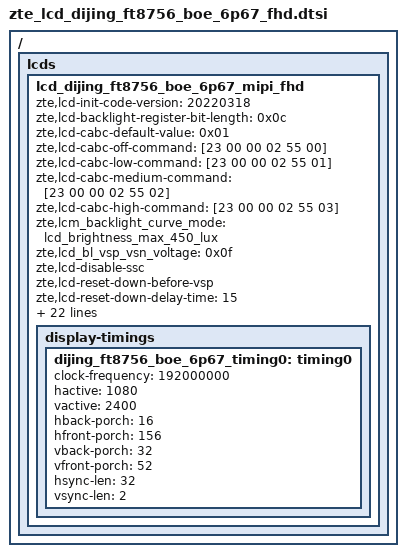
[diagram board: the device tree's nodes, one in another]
/ { lcds {
	lcd_dijing_ft8756_boe_6p67_mipi_fhd: lcd_dijing_ft8756_boe_6p67_mipi_fhd {
		zte,lcd-init-code-version = "20220318";
		zte,lcd-backlight-register-bit-length = <0x0c>;
		zte,lcd-cabc-default-value = <0x01>;
		zte,lcd-cabc-off-command = [23 00 00 02 55 00];
		zte,lcd-cabc-low-command = [23 00 00 02 55 01];
		zte,lcd-cabc-medium-command = [23 00 00 02 55 02];
		zte,lcd-cabc-high-command = [23 00 00 02 55 03];
		zte,lcm_backlight_curve_mode = "lcd_brightness_max_450_lux";
		zte,lcd_bl_vsp_vsn_voltage = <0x0f>;
		zte,lcd-disable-ssc;
		zte,lcd-reset-down-before-vsp;
		zte,lcd-reset-down-delay-time = <15>;
		zte,panel-name = "lcd_dijing_focal_ft8756_boe_6p67_mipi_fhd";

		sprd,dsi-work-mode = <1>; /* video burst mode*/
		sprd,dsi-lane-number = <4>;
		sprd,dsi-color-format = "rgb888";

		sprd,phy-bit-clock = <1296000>;  /* kbps */
		sprd,phy-escape-clock = <20000>;/* kHz */

		sprd,width-mm = <69498>;
		sprd,height-mm = <154440>;

		sprd,esd-check-enable = <0>;/* 0:close , 1:open */
		sprd,esd-check-mode = <0>;/* 0:REG ,1:TE  */
		sprd,esd-check-period = <3000>;
		sprd,esd-check-register = <0x0A>;
		sprd,esd-check-value = <0x9c>;

		sprd,reset-on-sequence = <1 10>, <0 10>, <1 50>;
		sprd,reset-off-sequence = <1 5>;

		sprd,initial-command = [
			39 00 00 02 00 00
			39 00 00 04 FF 87 56 01

			39 00 00 02 00 80
			39 00 00 03 FF 87 56

			39 00 00 02 00 A1
			39 00 00 07 B3 04 38 09 60 00 FC

			39 00 00 02 00 80
			39 00 00 07 C0 00 87 00 34 00 22

			39 00 00 02 00 90
			39 00 00 07 C0 00 87 00 34 00 22

			39 00 00 02 00 A0
			39 00 00 07 C0 01 0A 00 34 00 22

			39 00 00 02 00 B0
			39 00 00 06 C0 00 87 00 34 22

			39 00 00 02 00 C1
			39 00 00 09 C0 00 C7 00 9B 00 85 00 E8

			39 00 00 02 00 D7
			39 00 00 07 C0 00 85 00 34 00 22

			39 00 00 02 00 A3
			39 00 00 07 C1 00 32 00 32 00 02

			39 00 00 02 00 80
			39 00 00 11 CE 01 81 09 13 00 EC 00 EC 00
						92 00 92 00 74 00 74

			39 00 00 02 00 90
			39 00 00 10 CE 00 8E 0E B6 00 8E 80 09 13
						00 04 00 1B 1B 15

			39 00 00 02 00 A0
			39 00 00 04 CE 20 00 00

			39 00 00 02 00 B0
			39 00 00 04 CE 22 00 00

			39 00 00 02 00 D1
			39 00 00 08 CE 00 00 01 00 00 00 00

			39 00 00 02 00 E1
			39 00 00 0C CE 08 02 4D 02 4D 02 4D 00 00 00 00

			39 00 00 02 00 F1
			39 00 00 0A CE 16 0B 0F 01 27 01 28 01 16

			39 00 00 02 00 B0
			39 00 00 05 CF 00 00 DA DE

			39 00 00 02 00 B5
			39 00 00 05 CF 05 05 12 16

			39 00 00 02 00 C0
			39 00 00 05 CF 09 09 4C 50

			39 00 00 02 00 C5
			39 00 00 05 CF 00 00 08 0C

			39 00 00 02 00 E8
			39 00 00 02 C0 40

			39 00 00 02 00 CA
			39 00 00 02 C0 80

			39 00 00 02 00 80
			39 00 00 09 c2 83 01 01 81 82 01 01 81

			39 00 00 02 00 a0
			39 00 00 10 c2 8a 0a 00 00 86 89 0a 00 00
						86 88 0a 00 00 86

			39 00 00 02 00 b0
			39 00 00 06 c2 87 0a 00 00 86

			39 00 00 02 00 e0
			39 00 00 0F c2 33 33 33 33 33 33 00 00 03
						09 10 6a 01 81

			39 00 00 02 00 80
			39 00 00 11 cb fd fd 3c 30 fd 0c 1c fd 02
						fe fd fd fd fd 00 fc

			39 00 00 02 00 90
			39 00 00 11 cb ff 00 00 00 ff 00 00 00 00
						ff 00 00 00 00 00 00

			39 00 00 02 00 a0
			39 00 00 05 cb 00 00 00 00

			39 00 00 02 00 b0
			39 00 00 05 cb 50 41 A4 50

			39 00 00 02 00 c0
			39 00 00 05 cb 50 41 A4 50

			39 00 00 02 00 80
			39 00 00 11 cc 25 25 00 24 29 29 1b 18 1a
						17 19 16 00 00 00 00

			39 00 00 02 00 90
			39 00 00 09 cc 07 09 01 26 26 22 24 03

			39 00 00 02 00 80
			39 00 00 11 cd 25 25 00 24 29 29 1b 18 1a
						17 19 16 00 00 00 00

			39 00 00 02 00 90
			39 00 00 09 cd 06 08 01 26 26 22 24 02

			39 00 00 02 00 a0
			39 00 00 11 cc 25 25 00 24 00 00 1b 18 1a
						17 19 16 00 00 00 00

			39 00 00 02 00 b0
			39 00 00 09 cc 08 06 01 26 26 24 23 02

			39 00 00 02 00 a0
			39 00 00 11 cd 25 25 00 24 00 00 1b 18 1a
						17 19 16 00 00 00 00

			39 00 00 02 00 b0
			39 00 00 09 cd 09 07 01 26 26 24 23 03

			39 00 00 02 00 A0
			39 00 00 04 C4 8d d8 8d

			39 00 00 02 00 93
			39 00 00 02 C5 DA

			39 00 00 02 00 A4
			39 00 00 02 D7 00

			39 00 00 02 00 9B
			39 00 00 02 F5 4B

			39 00 00 02 00 93
			39 00 00 03 F5 00 00

			39 00 00 02 00 9D
			39 00 00 02 F5 49

			39 00 00 02 00 82
			39 00 00 03 F5 00 00

			39 00 00 02 00 80
			39 00 00 03 F5 59 59

			39 00 00 02 00 84
			39 00 00 04 F5 59 59 59

			39 00 00 02 00 96
			39 00 00 02 F5 59

			39 00 00 02 00 A6
			39 00 00 02 F5 59

			39 00 00 02 00 CA
			39 00 00 02 C0 80

			39 00 00 02 00 B1
			39 00 00 02 F5 1f

			39 00 00 02 00 00
			39 00 00 03 D8 29 29

			39 00 00 02 00 00
			39 00 00 29 E1 00 01 03 09 09 13 1B 21 2C
						5C 34 3B 41 46 55 4B 53 5B 62
						66 6A 71 7A 82 33 8D 92 99 A0
						37 A9 B4 C2 CB F2 D7 E8 F6 FF
						67
			39 00 00 02 00 00
			39 00 00 29 E2 00 01 03 09 09 14 1D 23 2E
						1C 36 3D 43 48 55 4D 55 5D 64
						66 6B 72 7A 82 93 8D 92 99 A0
						37 A9 B4 C2 CB F2 D7 E8 F6 FF
						67
			39 00 00 02 00 00
			39 00 00 29 E3 00 01 03 09 09 13 1B 21 2C
						5C 34 3B 41 46 55 4B 53 5B 62
						66 6A 71 7A 82 33 8D 92 99 A0
						37 A9 B4 C2 CB F2 D7 E8 F6 FF
						67
			39 00 00 02 00 00
			39 00 00 29 E4 00 01 03 09 09 14 1D 23 2E
						1C 36 3D 43 48 55 4D 55 5D 64
						66 6B 72 7A 82 93 8D 92 99 A0
						37 A9 B4 C2 CB F2 D7 E8 F6 FF
						67
			39 00 00 02 00 00
			39 00 00 29 E5 00 01 03 09 09 13 1B 21 2C
						5C 34 3B 41 46 55 4B 53 5B 62
						66 6A 71 7A 82 33 8D 92 99 A0
						37 A9 B4 C2 CB F2 D7 E8 F6 FF
						67
			39 00 00 02 00 00
			39 00 00 29 E6 00 01 03 09 09 14 1D 23 2E
						1C 36 3D 43 48 55 4D 55 5D 64
						66 6B 72 7A 82 93 8D 92 99 A0
						37 A9 B4 C2 CB F2 D7 E8 F6 FF
						67

			39 00 00 02 00 93
			39 00 00 02 C5 DF

			39 00 00 02 00 97
			39 00 00 02 C5 DF

			39 00 00 02 00 9A
			39 00 00 02 C5 23

			39 00 00 02 00 9C
			39 00 00 02 C5 23

			39 00 00 02 00 B6
			39 00 00 05 C5 19 19 19 19

			39 00 00 02 00 85
			39 00 00 02 C4 1C

			39 00 00 02 00 80
			39 00 00 02 A4 6C

			39 00 00 02 00 8D
			39 00 00 02 A5 06

			39 00 00 02 00 c6
			39 00 00 02 F5 02

			39 00 00 02 00 a9
			39 00 00 02 F5 c1

			39 00 00 02 00 b1
			39 00 00 02 c5 8a

			39 00 00 02 00 b4
			39 00 00 02 c5 8a

			39 00 00 02 00 A0
			39 00 00 11 C3 15 01 23 45 54 32 10 00 00
						00 34 50 12 21 05 43

			39 00 00 02 00 8C
			39 00 00 04 C3 00 00 00
			39 00 00 02 00 89
			39 00 00 04 c0 02 0c 07

			39 00 00 02 00 CB
			39 00 00 02 C0 19

			39 00 00 02 00 84
			39 00 00 03 c5 26 26

			39 00 00 02 00 80
			39 00 00 02 A4 6C

			39 00 00 02 00 97
			39 00 00 02 C4 01

			39 00 00 02 00 D0
			39 00 00 0d C3 46 00 00 00 46 00 00 00 46
						00 00 00

			39 00 00 02 35 00
			39 00 00 02 55 00
			05 78 00 01 11
			05 0A 00 01 29
			];

		sprd,sleep-in-command = [
			13 14 00 01 28
			13 C8 00 01 10
			39 00 00 02 00 00
			39 00 00 05 F7 5A A5 87 16
			];
		sprd,sleep-out-command = [
			13 55 00 01 11
			13 0A 00 01 29
			];

		display-timings {
			dijing_ft8756_boe_6p67_timing0: timing0 {
				clock-frequency = <192000000>;
				hactive = <1080>;
				vactive = <2400>;
				hback-porch = <16>;
				hfront-porch = <156>;
				vback-porch = <32>;
				vfront-porch = <52>;
				hsync-len = <32>;
				vsync-len = <2>;
			};
		};
	};
}; };
